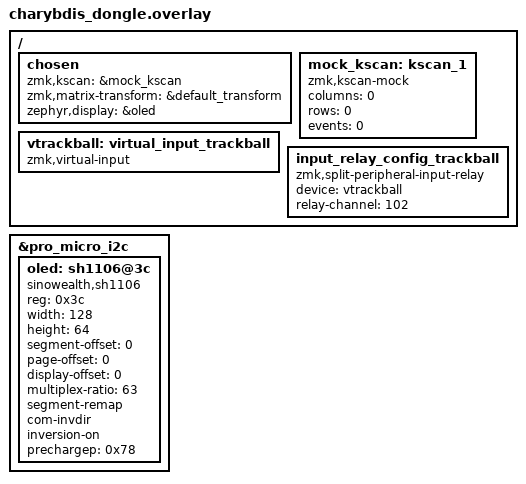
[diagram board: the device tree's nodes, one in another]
#include "charybdis.dtsi"

/ {
    chosen {
        zmk,kscan = &mock_kscan;
        zmk,matrix-transform = &default_transform;
        zephyr,display = &oled;
    };
    mock_kscan: kscan_1 {
        compatible = "zmk,kscan-mock";
        columns = <0>;
        rows = <0>;
        events = <0>;
    };
};

/ {
	vtrackball: virtual_input_trackball {
		compatible = "zmk,virtual-input";
	};

	input_relay_config_trackball {
		compatible = "zmk,split-peripheral-input-relay";
		device = <&vtrackball>;
		relay-channel = <102>;
	};
};

&pro_micro_i2c {
    status = "okay";
    oled: sh1106@3c {
        compatible = "sinowealth,sh1106";
        reg = <0x3c>;
        width = <128>;
        height = <64>;
        segment-offset = <0>;
        page-offset = <0>;
        display-offset = <0>;
        multiplex-ratio = <63>;
        segment-remap;
        com-invdir;
        inversion-on;
        prechargep = <0x78>;
        };
}; 
